# PY32F032xx register map
Vendor: Puya; Series: PY32F0; File version: 1.0.0
CPU: CM0+ r0p1, little endian, no MPU, no FPU, 4 interrupt priority bits
Registers are 32-bit, read-write, reset 0x0 unless marked. A register's access mark holds for its fields unless they carry their own. Offsets are from the block's base; [hi:lo] are bit positions; {n}, {i} and the like mark numbered series.

## EXTI — External interrupt/eventcontroller
Base 0x40021800
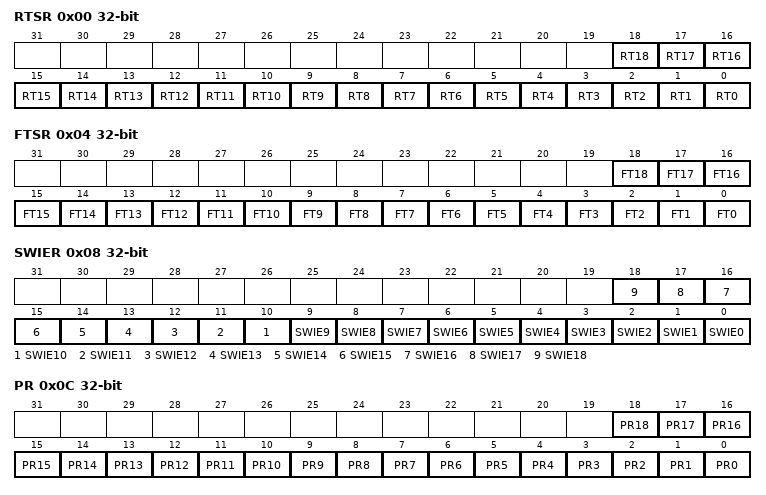
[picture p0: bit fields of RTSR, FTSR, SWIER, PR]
0x00 RTSR — EXTI rising trigger selectionregister
  [n] RT{n} (n=0..18)
0x04 FTSR — EXTI falling trigger selectionregister
  [n] FT{n} (n=0..18)
0x08 SWIER — EXTI software interrupt eventregister
  [n] SWIE{n} (n=0..18)
0x0C PR — EXTI pendingregister
  [n] PR{n} (n=0..18)
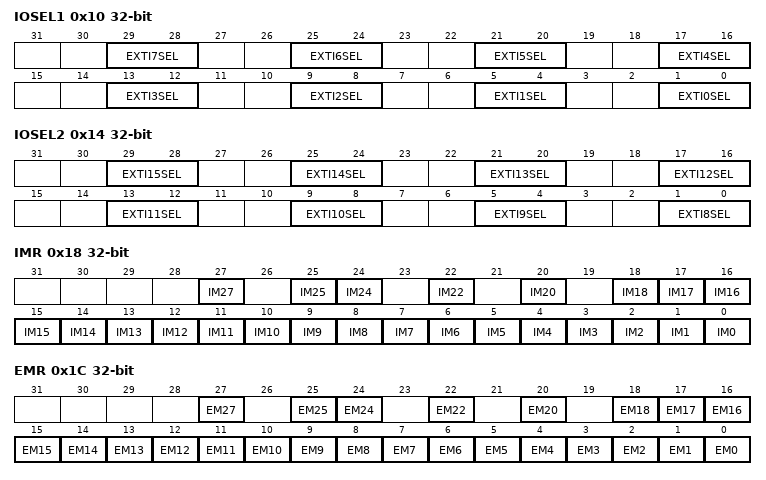
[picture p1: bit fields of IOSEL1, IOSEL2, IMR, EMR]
0x10 IOSEL1
  [all] fields
    1=0; 2=1
  [4n+1:4n] EXTI{n}SEL (n=0..7)
0x14 IOSEL2
  [all] fields
    1=0; 2=1
  [4n-31:4n-32] EXTI{n}SEL (n=8..15)
0x18 IMR — EXTI CPU wakeup with interrupt maskregister
  [27] IM27, [25] IM25, [24] IM24, [22] IM22, [20] IM20, [n] IM{n} (n=0..18)
0x1C EMR — EXTI CPU wakeup with event maskregister
  [27] EM27, [25] EM25, [24] EM24, [22] EM22, [20] EM20, [n] EM{n} (n=0..18)

## FLASH
Base 0x40022000
0x00 ACR — Access control register
  [1:0] LATENCY
    1=0; 2=1
0x08 KEYR — Flash key register
  [31:0] KEY wo — Flash CR key
0x0C OPTKEYR — Option byte key register
  [31:0] OPTKEY wo — Flash Option key
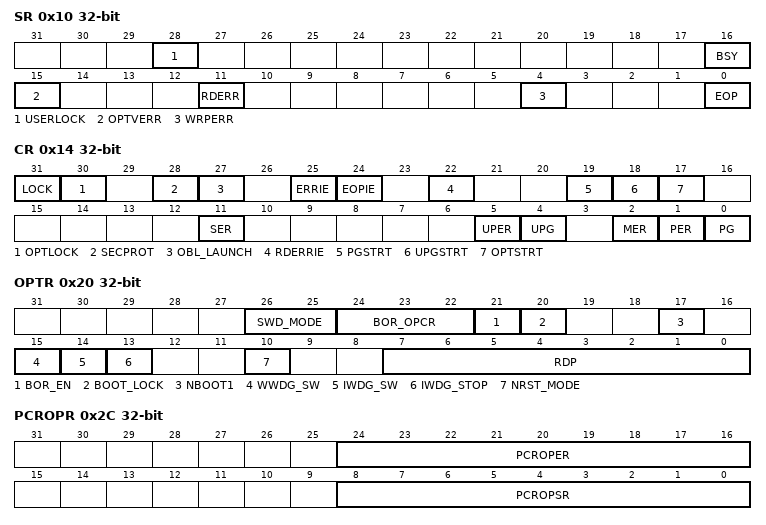
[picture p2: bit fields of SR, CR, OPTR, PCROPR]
0x10 SR — Status register
  [28] USERLOCK ro — User data lock
  [16] BSY ro — Bank Busy
  [15] OPTVERR — Option and trimming bits loading validity error
  [11] RDERR — Bank pcrop read error
  [4] WRPERR — Write protection error
  [0] EOP — End of operation
0x14 CR — Flash control register
  [31] LOCK
  [30] OPTLOCK — Option Lock
  [28] SECPROT — Secure protect
  [27] OBL_LAUNCH — Force the option bytes loading
  [25] ERRIE — Error interrupt enable
  [24] EOPIE — End of operation interrupt enable
  [22] RDERRIE — Bank pcrop read error interrupt enable
  [19] PGSTRT — Programming Start
  [18] UPGSTRT — Userdata Programming Start
  [17] OPTSTRT — Option bytes Programming Start
  [11] SER — Sector Erase
  [5] UPER — Userdata Page Erase
  [4] UPG — Userdata Program
  [2] MER — Bank Mass Erase
  [1] PER — Page Erase
  [0] PG — Page Program
0x20 OPTR — Flash option register
  [26:25] SWD_MODE
    1=0; 2=1
  [24:22] BOR_OPCR — BOR Level
    1=0; 2=1; 4=2
  [21] BOR_EN — BOR enable
  [20] BOOT_LOCK
  [17] NBOOT1
  [15] WWDG_SW — WWDG Software Enable
  [14] IWDG_SW — IWDG Software Enable
  [13] IWDG_STOP — IWDG Stop Count Control
  [10] NRST_MODE
  [7:0] RDP — Read Protection
0x28 WRPR
  [15:0] BK_WRPX — Bank Sector Write Protection
0x2C PCROPR
  [24:16] PCROPER — Bank pcrop end address
  [8:0] PCROPSR — Bank pcrop start address
0x30 SECR
  [8:0] SEC_SIZE — Bank securable seize
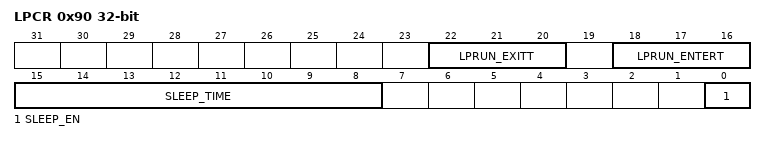
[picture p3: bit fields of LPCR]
0x90 LPCR
  [22:20] LPRUN_EXITT — Low power run mode exit time
    1=0; 2=1; 4=2
  [18:16] LPRUN_ENTERT — Low power run mode enter time
    1=0; 2=1; 4=2
  [15:8] SLEEP_TIME
  [0] SLEEP_EN — Sleep enable
0x100 TS0 — Flash TS0 register
  [6:0] TS0
0x104 TS1 — Flash TS1 register
  [6:0] TS1
0x108 TS2P — Flash TS2P register
  [6:0] TS2P
0x10C TPS3 — Flash TPS3 register
  [8:0] TPS3
0x110 TS3 — Flash TS3 register
  [6:0] TS3
0x114 ERSTPE
  [14:0] ERSTPE
0x118 PRGTPE — Flash PRGTPE register
  [14:0] PRGTPE
0x11C PRETPE — Flash PRETPE register
  [11:0] PRETPE
0x120 TACLK2PW
  [3:0] TACLK2PW

## GPIOA — General-purpose I/Os
Base 0x50000000
Same registers: GPIOB 0x50000400, GPIOF 0x50001400
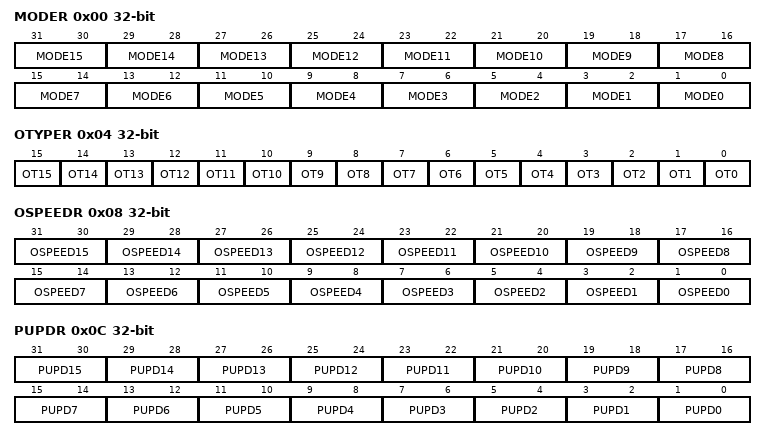
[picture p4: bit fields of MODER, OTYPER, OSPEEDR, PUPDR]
0x00 MODER — GPIO port mode register
  [all] fields
    1=0; 2=1
  [2n+1:2n] MODE{n} (n=0..15) — Port x configuration bits (y = 0..15)
0x04 OTYPER — GPIO port output type register
  [n] OT{n} (n=0..15) — Port x configuration bits (y = 0..15)
0x08 OSPEEDR — GPIO port output speed register
  [all] fields
    1=0; 2=1
  [2n+1:2n] OSPEED{n} (n=0..15) — Port x configuration bits (y = 0..15)
0x0C PUPDR — GPIO port pull-up/pull-down register
  [all] fields
    1=0; 2=1
  [2n+1:2n] PUPD{n} (n=0..15) — Port x configuration bits (y = 0..15)
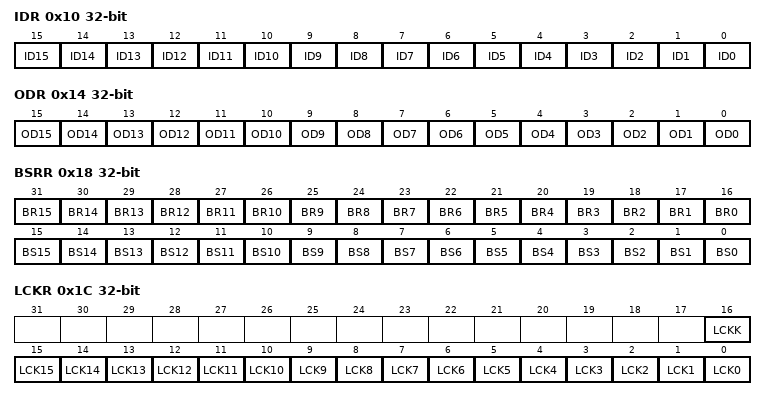
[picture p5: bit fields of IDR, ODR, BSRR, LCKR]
0x10 IDR — GPIO port input data register
  [n] ID{n} ro (n=0..15) — Port input data (y = 0..15)
0x14 ODR — GPIO port output data register
  [n] OD{n} (n=0..15) — Port output data (y = 0..15)
0x18 BSRR — GPIO port bit set/reset register
  [n+16] BR{n} (n=1..15) — Port x reset bit y (y = 0..15)
  [16] BR0 — Port x set bit y (y= 0..15)
  [n] BS{n} (n=0..15) — Port x set bit y (y= 0..15)
0x1C LCKR — GPIO port configuration lock register
  [16] LCKK — Port x lock bit y (y= 0..15)
  [n] LCK{n} (n=0..15) — Port x lock bit y (y= 0..15)
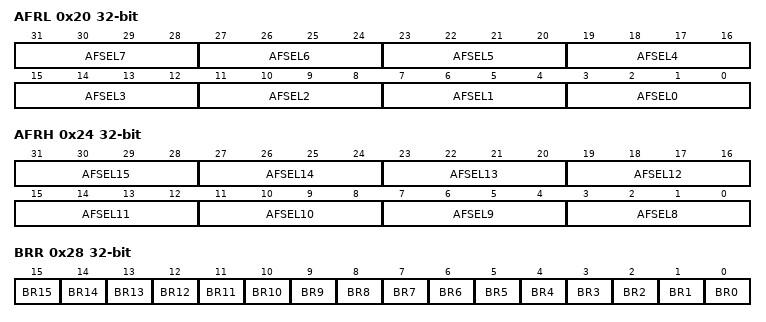
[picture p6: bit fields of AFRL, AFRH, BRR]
0x20 AFRL — GPIO alternate function low register
  [all] fields
    1=0; 2=1; 4=2; 8=3
  [4n+3:4n] AFSEL{n} (n=0..7) — Alternate function selection for port x bit y (y = 0..7)
0x24 AFRH — GPIO alternate function highregister
  [all] fields
    1=0; 2=1; 4=2; 8=3
  [4n-29:4n-32] AFSEL{n} (n=8..15) — Alternate function selection for port x bit y (y = 8..15)
0x28 BRR — port bit reset register
  [n] BR{n} (n=0..15) — Port Reset bit
